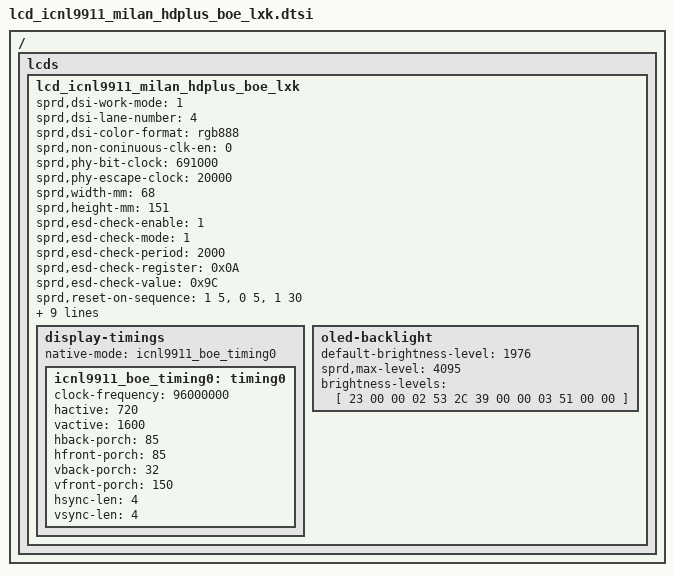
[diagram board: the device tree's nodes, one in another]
/ {
	fragment {
		target-path = "/";
		__overlay__ {
			lcds {
				lcd_icnl9911_milan_hdplus_boe_lxk: lcd_icnl9911_milan_hdplus_boe_lxk {

					sprd,dsi-work-mode = <1>;
					sprd,dsi-lane-number = <4>;
					sprd,dsi-color-format = "rgb888";
					sprd,non-coninuous-clk-en = <0>;

					sprd,phy-bit-clock = <691000>;
					sprd,phy-escape-clock = <20000>;

					sprd,width-mm = <68>;
					sprd,height-mm = <151>;

					sprd,esd-check-enable = <1>;
					sprd,esd-check-mode = <1>;  /*Read register*/
					sprd,esd-check-period = <2000>;
					sprd,esd-check-register = <0x0A>;
					sprd,esd-check-value = <0x9C>;

					sprd,reset-on-sequence = <1 5>, <0 5>, <1 30>;
					sprd,reset-off-sequence = <1 40>;

					sprd,initial-command = [
							39 00 00 03 F0 5A 59
							39 00 00 03 F1 A5 A6
							39 00 00 21 B0 89 88 87 86 02 03 04 05 33 33 33 33 16 02 02 61 02 02 00 05 04 03 02 01 02 03 04 00 00 00 00 00
							39 00 00 21 B1 53 42 85 81 1A 02 02 73 02 02 04 08 54 00 00 00 44 40 02 01 40 02 01 40 02 01 40 02 01 00 00 00
							39 00 00 12 B2 54 C4 82 05 40 02 01 40 02 01 05 05 54 0C 0C 0D 0B
							39 00 00 21 B3 02 10 08 10 08 26 26 91 A2 33 44 00 26 00 18 01 02 08 20 30 0E 07 00 00 78 00 78 08 09 22 33 00

							39 00 00 1D B4 43 1D E3 00 04 06 1C 22 10 12 0C 0E 43 43 43 43 43 43 43 43 43 43 FF FF FC 00 00 00
							39 00 00 1D B5 43 1D E3 00 05 07 1C 22 11 13 0D 0F 43 43 43 43 43 43 43 43 43 43 FF FF FC 00 00 00


							39 00 00 19 B8 00 00 00 00 00 00 00 00 00 00 00 00 00 00 00 00 00 00 00 00 00 00 00 00

							39 00 00 0E BB 01 05 09 11 0D 19 1D 55 25 69 00 21 25
							39 00 00 0F BC 00 00 00 00 02 20 FF 00 03 33 01 73 32 02
							39 00 00 0F BC 00 00 00 00 02 20 FF 00 03 33 01 73 33 02
							39 00 00 0B BD E9 02 4F CF 72 A4 08 44 AE 15
							39 00 00 0B BE 73 87 32 5A 0C 77 43 07 0E 0E
							39 00 00 09 BF 07 25 07 25 7F 00 11 04
							39 00 00 0A C0 10 00 1F FF FF FF 00 FF 00
							39 00 00 14 C1 C0 20 20 96 04 55 55 04 2A 40 36 00 07 CF FF FF C0 00 C0
							39 00 00 10 C2 CC 01 10 00 01 30 02 21 43 00 01 30 02 21 43
							39 00 00 0A C3 06 00 FF 00 FF 00 00 81 01
							39 00 00 0B C4 84 01 2B 41 00 3C 00 03 03 2E
							39 00 00 0C C5 03 1C C0 A0 80 10 42 44 08 0D 14
							39 00 00 0B C6 87 A2 24 22 22 31 7F 04 08 00

							39 00 00 17 C7 FA D5 BA A4 7C 5D 2E 7F 45 16 E7 B0 04 D5 B6 89 6F 47 1A 7F E4 00
							39 00 00 17 C8 FA D5 BA A4 7C 5D 2E 7F 45 16 E7 B0 04 D5 B6 89 6F 47 1A 7F E4 00
							23 00 00 02 CB 00
							39 00 00 06 D0 80 0D FF 0F 61
							23 00 00 02 D2 42
							39 00 00 05 FE FF FF FF 40

							39 00 00 18 E1 EF FE EE FE FE EE F0 67 33 FF E1 E1 E1 5D E1 33 E1 E1 E1 FF 00 07 FD
							39 00 00 1B E0 30 00 00 18 11 1F 22 62 DF A0 04 CC 01 FF FA FF F8 F8 F8 FA F8 FA FA FA FA FF
							39 00 00 03 F1 5A 59
							39 00 00 03 F0 A5 A6

							23 00 00 02 53 2C
							23 00 00 02 55 00
							23 00 00 02 35 00
							23 78 00 02 11 00
							23 0a 00 02 29 00
							23 05 00 02 26 01
						];
			sprd,page-unlock-command = [
			39 00 00 03 F0 5A 59
			39 00 00 03 F1 A5 A6
						];
			sprd,sleep-in-command = [
			23 00 00 02 26 08
			23 23 00 02 28 00
			23 78 00 02 10 00
						];
			sprd,sleep-out-command = [
			23 78 00 02 11 00
			23 23 00 02 29 00
			23 00 00 02 26 01
						];

					display-timings {
						native-mode = <&icnl9911_boe_timing0>;

						icnl9911_boe_timing0: timing0 {
							clock-frequency = <96000000>;
				hactive = <720>;
				vactive = <1600>;
				hback-porch = <85>;
				hfront-porch = <85>;
				vback-porch = <32>;
				vfront-porch = <150>;
				hsync-len = <4>;
				vsync-len = <4>;
						};
					};
				oled-backlight {
						default-brightness-level = <1976>;
						sprd,max-level = <4095>;
						brightness-levels = [
							23 00 00 02 53 2C
            		    	39 00 00 03 51 00 00
						];
					};

				};
			};
		};
	};
};
